# ATSAM4E16C register map
Vendor: Atmel; Series: SAM4E; File version: 0
CPU: CM4 r0p1, selectable endian, MPU, FPU, 4 interrupt priority bits
Registers are 32-bit, read-write, reset 0x0 unless marked. A register's access mark holds for its fields unless they carry their own. Offsets are from the block's base; [hi:lo] are bit positions; {n}, {i} and the like mark numbered series.

## ACC — Analog Comparator Controller
Base 0x400BC000; register names take the prefix ACC_
0x00 CR wo reset not defined — Control Register
  [0] SWRST — SoftWare ReSeT
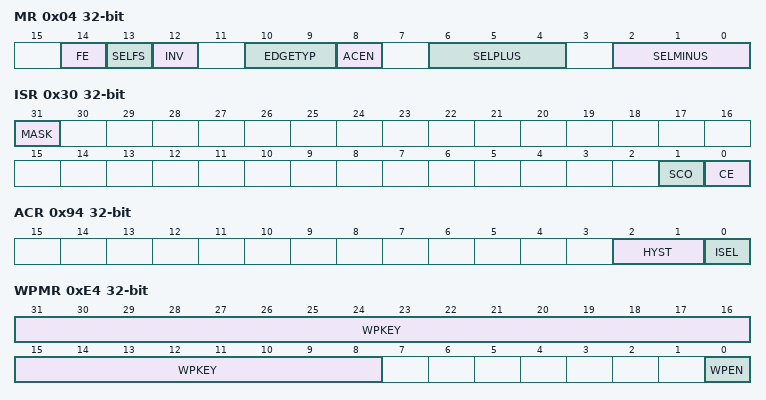
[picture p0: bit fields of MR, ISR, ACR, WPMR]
0x04 MR — Mode Register
  [14] FE — Fault Enable
    0=DIS (the FAULT output is tied to 0.); 1=EN (the FAULT output is driven by the signal defined by SELFS.)
  [13] SELFS — SELection of Fault Source
    0=CF (the CF flag is used to drive the FAULT output.); 1=OUTPUT (the output of the Analog Comparator flag is used to drive the FAULT output.)
  [12] INV — INVert comparator output
    0=DIS (Analog Comparator output is directly processed.); 1=EN (Analog Comparator output is inverted prior to being processed.)
  [10:9] EDGETYP — EDGE TYPe
    0=RISING (only rising edge of comparator output); 1=FALLING (falling edge of comparator output); 2=ANY (any edge of comparator output)
  [8] ACEN — Analog Comparator ENable
    0=DIS (Analog Comparator Disabled.); 1=EN (Analog Comparator Enabled.)
  [6:4] SELPLUS — SELection for PLUS comparator input
    {v}=AD{v} (Select AD{v}) (v=0..7)
  [2:0] SELMINUS — SELection for MINUS comparator input
    0=TS (SelectTS); 1=ADVREF (Select ADVREF); 2=DAC0 (Select DAC0); 3=DAC1 (Select DAC1); {v}=AD{v-4} (Select AD{v-4}) (v=4..7)
0x24 IER wo reset not defined — Interrupt Enable Register
  [0] CE — Comparison Edge
0x28 IDR wo reset not defined — Interrupt Disable Register
  [0] CE — Comparison Edge
0x2C IMR ro — Interrupt Mask Register
  [0] CE — Comparison Edge
0x30 ISR ro — Interrupt Status Register
  [31] MASK
  [1] SCO — Synchronized Comparator Output
  [0] CE — Comparison Edge
0x94 ACR — Analog Control Register
  [2:1] HYST — HYSTeresis selection
  [0] ISEL — Current SELection
    0=LOPW (low power option.); 1=HISP (high speed option.)
0xE4 WPMR — Write Protect Mode Register
  [31:8] WPKEY — Write Protect KEY
  [0] WPEN — Write Protect Enable
0xE8 WPSR ro — Write Protect Status Register
  [0] WPROTERR — Write PROTection ERRor

## CMCC — Cortex M Cache Controller
Base 0x400C4000; register names take the prefix CMCC_
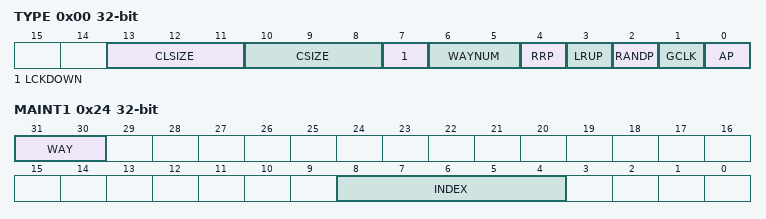
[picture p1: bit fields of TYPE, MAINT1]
0x00 TYPE ro reset not defined — Cache Type Register
  [13:11] CLSIZE — Cache Size
    0=CLSIZE_1KB (4 Bytes); 1=CLSIZE_2KB (8 Bytes); 2=CLSIZE_4KB (16 Bytes); 3=CLSIZE_8KB (32 Bytes)
  [10:8] CSIZE — Cache Size
    0=CSIZE_1KB (Cache Size 1 Kbytes); 1=CSIZE_2KB (Cache Size 2 Kbytes); 2=CSIZE_4KB (Cache Size 4 Kbytes); 3=CSIZE_8KB (Cache Size 8 Kbytes)
  [7] LCKDOWN — Lock Down Supported
  [6:5] WAYNUM — Number of Way
    0=DMAPPED (Direct Mapped Cache); 1=ARCH2WAY (2-WAY set associative); 2=ARCH4WAY (4-WAY set associative); 3=ARCH8WAY (8-WAY set associative)
  [4] RRP — Random Selection Policy Supported
  [3] LRUP — Least Recently Used Policy Supported
  [2] RANDP — Random Selection Policy Supported
  [1] GCLK — Dynamic Clock Gating Supported
  [0] AP — Access Port Access Allowed
0x04 CFG — Cache Configuration Register
  [0] GCLKDIS — Disable Clock Gating
0x08 CTRL wo — Cache Control Register
  [0] CEN — Cache Controller Enable
0x0C SR ro reset 0x1 — Cache Status Register
  [0] CSTS — Cache Controller Status
0x20 MAINT0 wo reset not defined — Cache Maintenance Register 0
  [0] INVALL — Cache Controller Invalidate All
0x24 MAINT1 wo reset not defined — Cache Maintenance Register 1
  [31:30] WAY — Invalidate Way
    {v}=Way {v} is selection for index invalidation (v=0..3)
  [8:4] INDEX — Invalidate Index
0x28 MCFG — Cache Monitor Configuration Register
  [1:0] MODE — Cache Controller Monitor Counter Mode
    0=CYCLE_COUNT (Cycle counter); 1=IHIT_COUNT (Instruction hit counter); 2=DHIT_COUNT (Data hit counter)
0x2C MEN — Cache Monitor Enable Register
  [0] MENABLE — Cache Controller Monitor Enable
0x30 MCTRL wo reset not defined — Cache Monitor Control Register
  [0] SWRST — Monitor
0x34 MSR ro — Cache Monitor Status Register
  [31:0] EVENT_CNT — Monitor Event Counter
